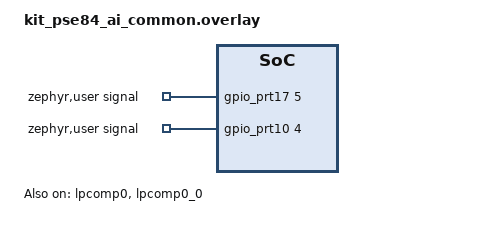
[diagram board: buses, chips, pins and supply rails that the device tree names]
/*
 * SPDX-FileCopyrightText: Copyright (c) 2026 Infineon Technologies AG,
 * SPDX-FileCopyrightText: or an affiliate of Infineon Technologies AG. All rights reserved.
 *
 * SPDX-License-Identifier: Apache-2.0
 */

/ {
	zephyr,user {
		signal-gpios = <&gpio_prt17 5 0>, <&gpio_prt10 4 0>;
	};
};

&gpio_prt10 {
	status = "okay";
};

&gpio_prt17 {
	status = "okay";
};

&lpcomp0 {
	status = "okay";
};

&lpcomp0_0 {
	output-mode = "direct";
	power = "ulp";
	intr-type = "both";
	input-p = "gpio";
	input-n = "local_vref";
	status = "okay";
};

&lpcomp0_1 {
	output-mode = "direct";
	power = "ulp";
	intr-type = "both";
	input-p = "gpio";
	input-n = "local_vref";
	status = "disabled";
};
